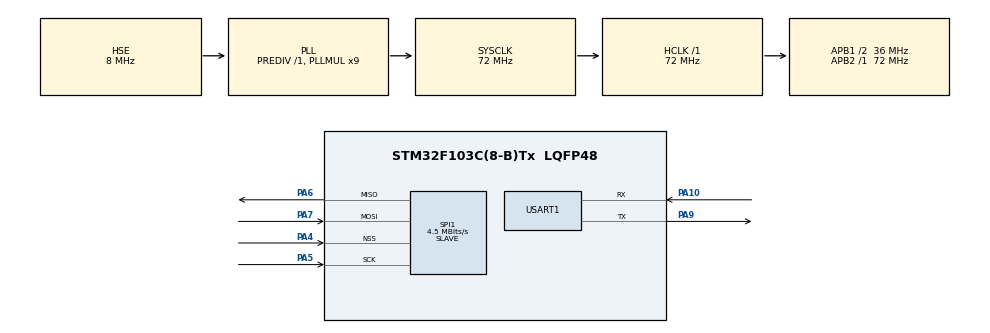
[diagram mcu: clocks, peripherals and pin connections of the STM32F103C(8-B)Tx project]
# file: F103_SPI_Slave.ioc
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Mcu.Family=STM32F1
RCC.PLLSourceVirtual=RCC_PLLSOURCE_HSE
Dma.SPI1_TX.1.Priority=DMA_PRIORITY_LOW
PA6.Mode=Full_Duplex_Slave
Dma.SPI1_TX.1.MemInc=DMA_MINC_ENABLE
PA7.Mode=Full_Duplex_Slave
PD1-OSC_OUT.Mode=HSE-External-Oscillator
PA10.Mode=Asynchronous
SPI1.VirtualType=VM_SLAVE
Dma.SPI1_TX.1.PeriphInc=DMA_PINC_DISABLE
PD0-OSC_IN.Signal=RCC_OSC_IN
Dma.SPI1_RX.0.Mode=DMA_CIRCULAR
RCC.APB1CLKDivider=RCC_HCLK_DIV2
Dma.SPI1_TX.1.Direction=DMA_MEMORY_TO_PERIPH
RCC.SYSCLKSource=RCC_SYSCLKSOURCE_PLLCLK
ProjectManager.StackSize=0x400
PD1-OSC_OUT.Signal=RCC_OSC_OUT
NVIC.DMA1_Channel3_IRQn=true\:0\:0\:false\:false\:true\:false\:true
PA13.Signal=SYS_JTMS-SWDIO
PA9.Mode=Asynchronous
Dma.SPI1_TX.1.MemDataAlignment=DMA_MDATAALIGN_BYTE
Dma.SPI1_RX.0.Direction=DMA_PERIPH_TO_MEMORY
PA4.Mode=NSS_Signal_Hard_Input
NVIC.DMA1_Channel2_IRQn=true\:0\:0\:false\:false\:true\:false\:true
ProjectManager.TargetToolchain=STM32CubeIDE
SPI1.Direction=SPI_DIRECTION_2LINES
RCC.HCLKFreq_Value=72000000
RCC.APB2TimFreq_Value=72000000
PA9.Signal=USART1_TX
SPI1.CalculateBaudRate=4.5 MBits/s
RCC.USBFreq_Value=72000000
RCC.AHBFreq_Value=72000000
PD0-OSC_IN.Mode=HSE-External-Oscillator
Dma.SPI1_TX.1.PeriphDataAlignment=DMA_PDATAALIGN_BYTE
PA5.Signal=SPI1_SCK
board=custom
RCC.PLLMUL=RCC_PLL_MUL9
Dma.SPI1_RX.0.PeriphInc=DMA_PINC_DISABLE
NVIC.SPI1_IRQn=true\:0\:0\:false\:false\:true\:true\:true
RCC.APB2Freq_Value=72000000
Dma.SPI1_TX.1.Mode=DMA_CIRCULAR
SPI1.Mode=SPI_MODE_SLAVE
PA14.Mode=Serial_Wire
Dma.SPI1_RX.0.Instance=DMA1_Channel2
Dma.SPI1_RX.0.PeriphDataAlignment=DMA_PDATAALIGN_BYTE
Dma.SPI1_RX.0.MemDataAlignment=DMA_MDATAALIGN_BYTE
SPI1.VirtualNSS=VM_NSSHARD
PA13.Mode=Serial_Wire
Mcu.Name=STM32F103C(8-B)Tx
Dma.SPI1_RX.0.MemInc=DMA_MINC_ENABLE
PA4.Signal=SPI1_NSS
RCC.SYSCLKFreq_VALUE=72000000
Mcu.Package=LQFP48
PA6.Signal=SPI1_MISO
USART1.VirtualMode=VM_ASYNC
PA10.Signal=USART1_RX
PA14.Signal=SYS_JTCK-SWCLK
ProjectManager.HeapSize=0x200
Dma.SPI1_RX.0.Priority=DMA_PRIORITY_LOW
NVIC.PriorityGroup=NVIC_PRIORITYGROUP_4
Dma.Request1=SPI1_TX
RCC.APB1TimFreq_Value=72000000
NVIC.USART1_IRQn=true\:0\:0\:false\:false\:true\:true\:true
Dma.Request0=SPI1_RX
RCC.APB1Freq_Value=36000000
SPI1.BaudRatePrescaler=SPI_BAUDRATEPRESCALER_16
Dma.SPI1_TX.1.Instance=DMA1_Channel3
PA5.Mode=Full_Duplex_Slave
PA7.Signal=SPI1_MOSI

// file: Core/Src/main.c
/* USER CODE BEGIN Header */
/**
  ******************************************************************************
  * @file           : main.c
  * @brief          : Main program body
  ******************************************************************************
  * @attention
  *
  * <h2><center>&copy; Copyright (c) 2021 STMicroelectronics.
  * All rights reserved.</center></h2>
  *
  * This software component is licensed by ST under BSD 3-Clause license,
  * the "License"; You may not use this file except in compliance with the
  * License. You may obtain a copy of the License at:
  *                        opensource.org/licenses/BSD-3-Clause
  *
  ******************************************************************************
  */
/* USER CODE END Header */
#include "main.h"
#include <stdio.h>
#include <string.h>

SPI_HandleTypeDef hspi1;
DMA_HandleTypeDef hdma_spi1_rx;
DMA_HandleTypeDef hdma_spi1_tx;

UART_HandleTypeDef huart1;

void SystemClock_Config(void);
static void MX_GPIO_Init(void);
static void MX_DMA_Init(void);
static void MX_SPI1_Init(void);
static void MX_USART1_UART_Init(void);
/* USER CODE BEGIN PFP */
int __io_putchar (int ch) {
	uint8_t c = ch;
	HAL_UART_Transmit(&huart1, &c, 1, HAL_MAX_DELAY);
	return ch;
}
/* USER CODE END PFP */

/* USER CODE BEGIN 0 */
uint8_t receive_data, send_data = 255;
/* USER CODE END 0 */

int main(void)
{

  /* MCU Configuration--------------------------------------------------------*/

  /* Reset of all peripherals, Initializes the Flash interface and the Systick. */
  HAL_Init();

  /* Configure the system clock */
  SystemClock_Config();

  /* Initialize all configured peripherals */
  MX_GPIO_Init();
  MX_DMA_Init();
  MX_SPI1_Init();
  MX_USART1_UART_Init();
  /* USER CODE BEGIN 2 */
  //HAL_SPI_Receive_DMA(&hspi1, &receive_data, 1);
  HAL_SPI_TransmitReceive_DMA(&hspi1, &send_data, &receive_data, 1);
  /* USER CODE END 2 */

  /* Infinite loop */
  while (1)
  {
	  printf("SPI RX = %d | TX = %d\r\n",receive_data,send_data);
	  send_data--;
	  HAL_Delay(1000);
  }
}

void SystemClock_Config(void)
{
  RCC_OscInitTypeDef RCC_OscInitStruct = {0};
  RCC_ClkInitTypeDef RCC_ClkInitStruct = {0};

  /** Initializes the RCC Oscillators according to the specified parameters
  * in the RCC_OscInitTypeDef structure.
  */
  RCC_OscInitStruct.OscillatorType = RCC_OSCILLATORTYPE_HSE;
  RCC_OscInitStruct.HSEState = RCC_HSE_ON;
  RCC_OscInitStruct.HSEPredivValue = RCC_HSE_PREDIV_DIV1;
  RCC_OscInitStruct.HSIState = RCC_HSI_ON;
  RCC_OscInitStruct.PLL.PLLState = RCC_PLL_ON;
  RCC_OscInitStruct.PLL.PLLSource = RCC_PLLSOURCE_HSE;
  RCC_OscInitStruct.PLL.PLLMUL = RCC_PLL_MUL9;
  if (HAL_RCC_OscConfig(&RCC_OscInitStruct) != HAL_OK)
  {
    Error_Handler();
  }
  /** Initializes the CPU, AHB and APB buses clocks
  */
  RCC_ClkInitStruct.ClockType = RCC_CLOCKTYPE_HCLK|RCC_CLOCKTYPE_SYSCLK
                              |RCC_CLOCKTYPE_PCLK1|RCC_CLOCKTYPE_PCLK2;
  RCC_ClkInitStruct.SYSCLKSource = RCC_SYSCLKSOURCE_PLLCLK;
  RCC_ClkInitStruct.AHBCLKDivider = RCC_SYSCLK_DIV1;
  RCC_ClkInitStruct.APB1CLKDivider = RCC_HCLK_DIV2;
  RCC_ClkInitStruct.APB2CLKDivider = RCC_HCLK_DIV1;

  if (HAL_RCC_ClockConfig(&RCC_ClkInitStruct, FLASH_LATENCY_2) != HAL_OK)
  {
    Error_Handler();
  }
}

static void MX_SPI1_Init(void)
{

  /* SPI1 parameter configuration*/
  hspi1.Instance = SPI1;
  hspi1.Init.Mode = SPI_MODE_SLAVE;
  hspi1.Init.Direction = SPI_DIRECTION_2LINES;
  hspi1.Init.DataSize = SPI_DATASIZE_8BIT;
  hspi1.Init.CLKPolarity = SPI_POLARITY_LOW;
  hspi1.Init.CLKPhase = SPI_PHASE_1EDGE;
  hspi1.Init.NSS = SPI_NSS_HARD_INPUT;
  hspi1.Init.BaudRatePrescaler = SPI_BAUDRATEPRESCALER_16;
  hspi1.Init.FirstBit = SPI_FIRSTBIT_MSB;
  hspi1.Init.TIMode = SPI_TIMODE_DISABLE;
  hspi1.Init.CRCCalculation = SPI_CRCCALCULATION_DISABLE;
  hspi1.Init.CRCPolynomial = 10;
  if (HAL_SPI_Init(&hspi1) != HAL_OK)
  {
    Error_Handler();
  }

}

static void MX_USART1_UART_Init(void)
{

  huart1.Instance = USART1;
  huart1.Init.BaudRate = 115200;
  huart1.Init.WordLength = UART_WORDLENGTH_8B;
  huart1.Init.StopBits = UART_STOPBITS_1;
  huart1.Init.Parity = UART_PARITY_NONE;
  huart1.Init.Mode = UART_MODE_TX_RX;
  huart1.Init.HwFlowCtl = UART_HWCONTROL_NONE;
  huart1.Init.OverSampling = UART_OVERSAMPLING_16;
  if (HAL_UART_Init(&huart1) != HAL_OK)
  {
    Error_Handler();
  }

}

static void MX_DMA_Init(void)
{

  /* DMA controller clock enable */
  __HAL_RCC_DMA1_CLK_ENABLE();

  /* DMA interrupt init */
  /* DMA1_Channel2_IRQn interrupt configuration */
  HAL_NVIC_SetPriority(DMA1_Channel2_IRQn, 0, 0);
  HAL_NVIC_EnableIRQ(DMA1_Channel2_IRQn);
  /* DMA1_Channel3_IRQn interrupt configuration */
  HAL_NVIC_SetPriority(DMA1_Channel3_IRQn, 0, 0);
  HAL_NVIC_EnableIRQ(DMA1_Channel3_IRQn);

}

static void MX_GPIO_Init(void)
{

  /* GPIO Ports Clock Enable */
  __HAL_RCC_GPIOD_CLK_ENABLE();
  __HAL_RCC_GPIOA_CLK_ENABLE();

}

void Error_Handler(void)
{
}

/************************ (C) COPYRIGHT STMicroelectronics *****END OF FILE****/
